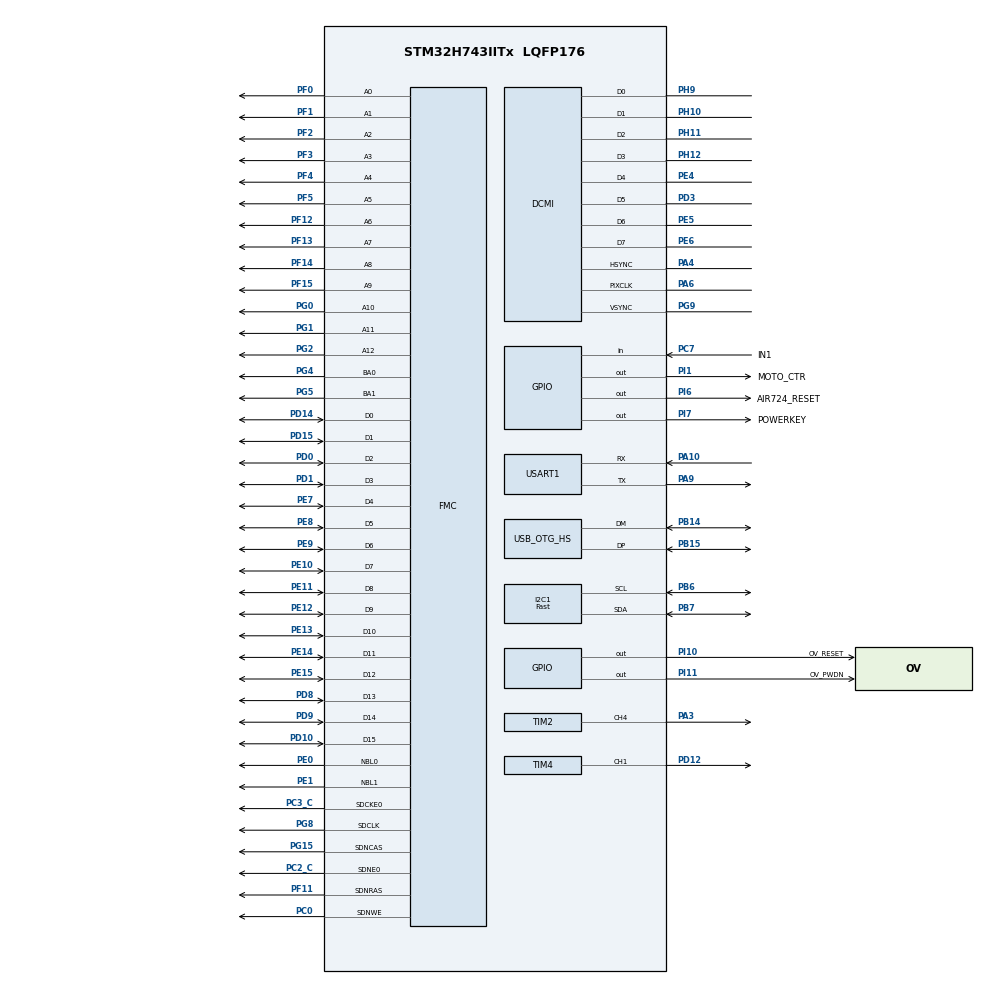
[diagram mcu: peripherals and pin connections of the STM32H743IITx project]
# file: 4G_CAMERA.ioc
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CORTEX_M7.AccessPermission_Spec=MPU_REGION_FULL_ACCESS
CORTEX_M7.BaseAddress_Spec=0x24000000
CORTEX_M7.CPU_DCache=Enabled
CORTEX_M7.CPU_ICache=Enabled
CORTEX_M7.DisableExec_Spec=MPU_INSTRUCTION_ACCESS_ENABLE
CORTEX_M7.Enable_S-Cortex_Memory_Protection_Unit_Region1_Settings_S=__NULL
CORTEX_M7.IsBufferable_Spec=MPU_ACCESS_BUFFERABLE
CORTEX_M7.IsCacheable_Spec=MPU_ACCESS_CACHEABLE
CORTEX_M7.IsShareable_Spec=MPU_ACCESS_NOT_SHAREABLE
CORTEX_M7.MPU_Control=MPU_PRIVILEGED_DEFAULT
CORTEX_M7.Size_Spec=MPU_REGION_SIZE_512KB
CORTEX_M7.SubRegionDisable_Spec=0x0
CORTEX_M7.TypeExtField_Spec=MPU_TEX_LEVEL0
CORTEX_M7.default_mode_Activation=1
DCMI.HSPolarity=DCMI_HSPOLARITY_LOW
DCMI.JPEGMode=DCMI_JPEG_DISABLE
DCMI.PCKPolarity=DCMI_PCKPOLARITY_RISING
DCMI.VSPolarity=DCMI_VSPOLARITY_HIGH
Dma.DCMI.0.Direction=DMA_PERIPH_TO_MEMORY
Dma.DCMI.0.EventEnable=DISABLE
Dma.DCMI.0.FIFOMode=DMA_FIFOMODE_ENABLE
Dma.DCMI.0.FIFOThreshold=DMA_FIFO_THRESHOLD_FULL
Dma.DCMI.0.Instance=DMA1_Stream0
Dma.DCMI.0.MemBurst=DMA_MBURST_SINGLE
Dma.DCMI.0.MemDataAlignment=DMA_MDATAALIGN_WORD
Dma.DCMI.0.MemInc=DMA_MINC_ENABLE
Dma.DCMI.0.Mode=DMA_NORMAL
Dma.DCMI.0.PeriphBurst=DMA_PBURST_SINGLE
Dma.DCMI.0.PeriphDataAlignment=DMA_PDATAALIGN_WORD
Dma.DCMI.0.PeriphInc=DMA_PINC_DISABLE
Dma.DCMI.0.Polarity=HAL_DMAMUX_REQ_GEN_RISING
Dma.DCMI.0.Priority=DMA_PRIORITY_VERY_HIGH
Dma.DCMI.0.RequestNumber=1
Dma.DCMI.0.SignalID=NONE
Dma.DCMI.0.SyncEnable=DISABLE
Dma.DCMI.0.SyncPolarity=HAL_DMAMUX_SYNC_NO_EVENT
Dma.DCMI.0.SyncRequestNumber=1
Dma.DCMI.0.SyncSignalID=NONE
Dma.Request0=DCMI
FMC.CASLatency1=FMC_SDRAM_CAS_LATENCY_3
FMC.ColumnBitsNumber1=FMC_SDRAM_COLUMN_BITS_NUM_9
FMC.ExitSelfRefreshDelay1=8
FMC.LoadToActiveDelay1=2
FMC.RCDDelay1=2
FMC.RPDelay1=2
FMC.ReadBurst1=FMC_SDRAM_RBURST_ENABLE
FMC.ReadPipeDelay1=FMC_SDRAM_RPIPE_DELAY_1
FMC.RowCycleDelay1=6
FMC.SDClockPeriod1=FMC_SDRAM_CLOCK_PERIOD_2
FMC.SelfRefreshTime1=6
FMC.WriteRecoveryTime1=6
FREERTOS.Tasks01=defaultTask,24,128,StartDefaultTask,Default,NULL,Dynamic,NULL,NULL;cmdAnalysis,31,512,StartCmdAnalysis,Default,NULL,Dynamic,NULL,NULL;sendDataTask,30,512,StartSendDataTask,Default,NULL,Dynamic,NULL,NULL;ledTask,23,128,StartLedTask,Default,NULL,Dynamic,NULL,NULL;motoTask,8,128,StartMotoTask,Default,NULL,Dynamic,NULL,NULL
FREERTOS.configENABLE_FPU=1
I2C1.I2C_Speed_Mode=I2C_Fast
I2C1.Timing=0x00B03FDB
IWDG1.Prescaler=IWDG_PRESCALER_32
IWDG1.Reload=2000
JPEG.JPEG_RGB_FORMAT=JPEG_RGB565
JPEG.JPEG_SWAP_RG=0
Mcu.Family=STM32H7
Mcu.Name=STM32H743IITx
Mcu.Package=LQFP176
NVIC.DCMI_IRQn=true\:5\:0\:false\:false\:true\:true\:true\:true\:true
NVIC.DMA1_Stream0_IRQn=true\:5\:0\:false\:false\:true\:true\:false\:true\:true
NVIC.OTG_HS_IRQn=true\:5\:0\:false\:false\:true\:true\:false\:true\:true
NVIC.PriorityGroup=NVIC_PRIORITYGROUP_4
NVIC.RTC_WKUP_IRQn=true\:5\:0\:false\:false\:true\:true\:true\:true\:true
NVIC.TIM17_IRQn=true\:15\:0\:false\:false\:true\:false\:false\:true\:true
NVIC.TimeBase=TIM17_IRQn
NVIC.TimeBaseIP=TIM17
NVIC.USART1_IRQn=true\:5\:0\:false\:false\:true\:true\:true\:true\:true
PA10.Mode=Asynchronous
PA10.Signal=USART1_RX
PA13\ (JTMS/SWDIO).Mode=Serial_Wire
PA13\ (JTMS/SWDIO).Signal=DEBUG_JTMS-SWDIO
PA14\ (JTCK/SWCLK).Mode=Serial_Wire
PA14\ (JTCK/SWCLK).Signal=DEBUG_JTCK-SWCLK
PA3.Signal=S_TIM2_CH4
PA4.Mode=Slave_8_bits_External_Synchro
PA4.Signal=DCMI_HSYNC
PA6.Mode=Slave_8_bits_External_Synchro
PA6.Signal=DCMI_PIXCLK
PA9.Mode=Asynchronous
PA9.Signal=USART1_TX
PB14.Mode=Device_Only_FS
PB14.Signal=USB_OTG_HS_DM
PB15.Mode=Device_Only_FS
PB15.Signal=USB_OTG_HS_DP
PB6.Mode=I2C
PB6.Signal=I2C1_SCL
PB7.Mode=I2C
PB7.Signal=I2C1_SDA
PC0.Signal=FMC_SDNWE
PC14-OSC32_IN\ (OSC32_IN).Mode=LSE-External-Clock-Source
PC14-OSC32_IN\ (OSC32_IN).Signal=RCC_OSC32_IN
PC2_C.Mode=SdramChipSelect1_1
PC2_C.Signal=FMC_SDNE0
PC3_C.Mode=SdramChipSelect1_1
PC3_C.Signal=FMC_SDCKE0
PC7.GPIO_Label=IN1
PC7.Signal=GPIO_Input
PD0.Signal=FMC_D2_DA2
PD1.Signal=FMC_D3_DA3
PD10.Signal=FMC_D15_DA15
PD12.Signal=S_TIM4_CH1
PD14.Signal=FMC_D0_DA0
PD15.Signal=FMC_D1_DA1
PD3.Mode=Slave_8_bits_External_Synchro
PD3.Signal=DCMI_D5
PD8.Signal=FMC_D13_DA13
PD9.Signal=FMC_D14_DA14
PE0.Signal=FMC_NBL0
PE1.Signal=FMC_NBL1
PE10.Signal=FMC_D7_DA7
PE11.Signal=FMC_D8_DA8
PE12.Signal=FMC_D9_DA9
PE13.Signal=FMC_D10_DA10
PE14.Signal=FMC_D11_DA11
PE15.Signal=FMC_D12_DA12
PE4.Mode=Slave_8_bits_External_Synchro
PE4.Signal=DCMI_D4
PE5.Mode=Slave_8_bits_External_Synchro
PE5.Signal=DCMI_D6
PE6.Mode=Slave_8_bits_External_Synchro
PE6.Signal=DCMI_D7
PE7.Signal=FMC_D4_DA4
PE8.Signal=FMC_D5_DA5
PE9.Signal=FMC_D6_DA6
PF0.Signal=FMC_A0
PF1.Signal=FMC_A1
PF11.Signal=FMC_SDNRAS
PF12.Signal=FMC_A6
PF13.Signal=FMC_A7
PF14.Signal=FMC_A8
PF15.Signal=FMC_A9
PF2.Signal=FMC_A2
PF3.Signal=FMC_A3
PF4.Signal=FMC_A4
PF5.Signal=FMC_A5
PG0.Signal=FMC_A10
PG1.Signal=FMC_A11
PG15.Signal=FMC_SDNCAS
PG2.Signal=FMC_A12
PG4.Signal=FMC_A14_BA0
PG5.Signal=FMC_A15_BA1
PG8.Signal=FMC_SDCLK
PG9.Mode=Slave_8_bits_External_Synchro
PG9.Signal=DCMI_VSYNC
PH0-OSC_IN\ (PH0).Mode=HSE-External-Clock-Source
PH0-OSC_IN\ (PH0).Signal=RCC_OSC_IN
PH10.Mode=Slave_8_bits_External_Synchro
PH10.Signal=DCMI_D1
PH11.Mode=Slave_8_bits_External_Synchro
PH11.Signal=DCMI_D2
PH12.Mode=Slave_8_bits_External_Synchro
PH12.Signal=DCMI_D3
PH9.Mode=Slave_8_bits_External_Synchro
PH9.Signal=DCMI_D0
PI1.GPIO_Label=MOTO_CTR
PI1.GPIO_PuPd=GPIO_PULLUP
PI1.GPIO_Speed=GPIO_SPEED_FREQ_VERY_HIGH
PI1.Signal=GPIO_Output
PI10.GPIO_Label=OV_RESET
PI10.GPIO_PuPd=GPIO_PULLUP
PI10.GPIO_Speed=GPIO_SPEED_FREQ_VERY_HIGH
PI10.Signal=GPIO_Output
PI11.GPIO_Label=OV_PWDN
PI11.GPIO_ModeDefaultOutputPP=GPIO_MODE_OUTPUT_PP
PI11.GPIO_PuPd=GPIO_PULLUP
PI11.GPIO_Speed=GPIO_SPEED_FREQ_VERY_HIGH
PI11.Signal=GPIO_Output
PI6.GPIO_Label=AIR724_RESET
PI6.GPIO_PuPd=GPIO_PULLUP
PI6.GPIO_Speed=GPIO_SPEED_FREQ_VERY_HIGH
PI6.Signal=GPIO_Output
PI7.GPIO_Label=POWERKEY
PI7.GPIO_PuPd=GPIO_PULLUP
PI7.GPIO_Speed=GPIO_SPEED_FREQ_VERY_HIGH
PI7.Signal=GPIO_Output
ProjectManager.HeapSize=0x200
ProjectManager.StackSize=0x400
ProjectManager.TargetToolchain=MDK-ARM V5.32
RCC.ADCFreq_Value=75000000
RCC.APB1Freq_Value=120000000
RCC.APB2Freq_Value=120000000
RCC.APB3Freq_Value=120000000
RCC.APB4Freq_Value=120000000
RCC.CortexFreq_Value=480000000
RCC.D1PPRE=RCC_APB3_DIV2
RCC.D2PPRE1=RCC_APB1_DIV2
RCC.D2PPRE2=RCC_APB2_DIV2
RCC.D3PPRE=RCC_APB4_DIV2
RCC.DIVM1=1
RCC.DIVM2=1
RCC.DIVN1=80
RCC.DIVN2=12
RCC.DIVQ1=4
RCC.DIVR2=1
RCC.FMCCLockSelection=RCC_FMCCLKSOURCE_PLL2
RCC.HCLKFreq_Value=240000000
RCC.HPRE=RCC_HCLK_DIV2
RCC.HSE_VALUE=12000000
RCC.PLL2FRACN=4096
RCC.PLL3FRACN=0
RCC.PLLFRACN=0
RCC.PLLSourceVirtual=RCC_PLLSOURCE_HSE
RCC.ProductRev=revV
RCC.RCC_MCO1Source=RCC_MCO1SOURCE_HSE
RCC.RCC_MCO2Source=RCC_MCO2SOURCE_PLL2PCLK
RCC.RCC_TIM_PRescaler_Selection=RCC_TIMPRES_DESACTIVATED
RCC.RTCClockSelection=RCC_RTCCLKSOURCE_LSE
RCC.SYSCLKFreq_VALUE=480000000
RCC.SYSCLKSource=RCC_SYSCLKSOURCE_PLLCLK
RCC.SupplySource=PWR_LDO_SUPPLY
RCC.USBCLockSelection=RCC_USBCLKSOURCE_HSI48
RCC.USBFreq_Value=48000000
RTC.WakeUpClock-WakeUp=RTC_WAKEUPCLOCK_CK_SPRE_16BITS
RTC.WakeUpCounter-WakeUp=0
SH.FMC_A0.0=FMC_A0,13b-sda1
SH.FMC_A1.0=FMC_A1,13b-sda1
SH.FMC_A10.0=FMC_A10,13b-sda1
SH.FMC_A11.0=FMC_A11,13b-sda1
SH.FMC_A12.0=FMC_A12,13b-sda1
SH.FMC_A14_BA0.0=FMC_BA0,FourSdramBanks1
SH.FMC_A15_BA1.0=FMC_BA1,FourSdramBanks1
SH.FMC_A2.0=FMC_A2,13b-sda1
SH.FMC_A3.0=FMC_A3,13b-sda1
SH.FMC_A4.0=FMC_A4,13b-sda1
SH.FMC_A5.0=FMC_A5,13b-sda1
SH.FMC_A6.0=FMC_A6,13b-sda1
SH.FMC_A7.0=FMC_A7,13b-sda1
SH.FMC_A8.0=FMC_A8,13b-sda1
SH.FMC_A9.0=FMC_A9,13b-sda1
SH.FMC_D0_DA0.0=FMC_D0,sd-16b-d1
SH.FMC_D10_DA10.0=FMC_D10,sd-16b-d1
SH.FMC_D11_DA11.0=FMC_D11,sd-16b-d1
SH.FMC_D12_DA12.0=FMC_D12,sd-16b-d1
SH.FMC_D13_DA13.0=FMC_D13,sd-16b-d1
SH.FMC_D14_DA14.0=FMC_D14,sd-16b-d1
SH.FMC_D15_DA15.0=FMC_D15,sd-16b-d1
SH.FMC_D1_DA1.0=FMC_D1,sd-16b-d1
SH.FMC_D2_DA2.0=FMC_D2,sd-16b-d1
SH.FMC_D3_DA3.0=FMC_D3,sd-16b-d1
SH.FMC_D4_DA4.0=FMC_D4,sd-16b-d1
SH.FMC_D5_DA5.0=FMC_D5,sd-16b-d1
SH.FMC_D6_DA6.0=FMC_D6,sd-16b-d1
SH.FMC_D7_DA7.0=FMC_D7,sd-16b-d1
SH.FMC_D8_DA8.0=FMC_D8,sd-16b-d1
SH.FMC_D9_DA9.0=FMC_D9,sd-16b-d1
SH.FMC_NBL0.0=FMC_NBL0,Sd2ByteEnable1
SH.FMC_NBL1.0=FMC_NBL1,Sd2ByteEnable1
SH.FMC_SDCLK.0=FMC_SDCLK,13b-sda1
SH.FMC_SDNCAS.0=FMC_SDNCAS,13b-sda1
SH.FMC_SDNRAS.0=FMC_SDNRAS,13b-sda1
SH.FMC_SDNWE.0=FMC_SDNWE,13b-sda1
SH.S_TIM2_CH4.0=TIM2_CH4,PWM Generation4 CH4
SH.S_TIM4_CH1.0=TIM4_CH1,PWM Generation1 CH1
TIM2.Channel-PWM\ Generation4\ CH4=TIM_CHANNEL_4
TIM2.Period=100
TIM2.Prescaler=199
TIM4.Channel-PWM\ Generation1\ CH1=TIM_CHANNEL_1
TIM4.Period=100
TIM4.Prescaler=199
USART1.VirtualMode-Asynchronous=VM_ASYNC
USB_DEVICE.CLASS_NAME_HS=CDC
USB_DEVICE.VirtualMode-CDC_HS=Cdc
USB_DEVICE.VirtualModeHS=Cdc_HS
USB_OTG_HS.VirtualMode-Device_Only_FS=Device_Only_FS
VP_FREERTOS_VS_CMSIS_V2.Mode=CMSIS_V2
VP_IWDG1_VS_IWDG.Mode=IWDG_Activate
VP_JPEG_VS_JPEG.Mode=JPEG_Activate
VP_RTC_VS_RTC_Activate.Mode=RTC_Enabled
VP_RTC_VS_RTC_WakeUp_intern.Mode=WakeUp
VP_SYS_VS_tim17.Mode=TIM17
VP_TIM2_VS_ClockSourceINT.Mode=Internal
VP_TIM4_VS_ClockSourceINT.Mode=Internal
VP_USB_DEVICE_VS_USB_DEVICE_CDC_HS.Mode=CDC_HS
board=custom

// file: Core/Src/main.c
/* USER CODE BEGIN Header */
/**
  ******************************************************************************
  * @file           : main.c
  * @brief          : Main program body
  ******************************************************************************
  * @attention
  *
  * Copyright (c) 2024 STMicroelectronics.
  * All rights reserved.
  *
  * This software is licensed under terms that can be found in the LICENSE file
  * in the root directory of this software component.
  * If no LICENSE file comes with this software, it is provided AS-IS.
  *
  ******************************************************************************
  */
/* USER CODE END Header */
#include "main.h"
#include "cmsis_os.h"
#include "dcmi.h"
#include "dma.h"
#include "i2c.h"
#include "iwdg.h"
#include "jpeg.h"
#include "rtc.h"
#include "tim.h"
#include "usart.h"
#include "usb_device.h"
#include "gpio.h"
#include "fmc.h"

/* USER CODE BEGIN Includes */
#include "sdram.h"
#include "ov5640.h"
#include "flash.h"
#include "stm32h7xx_it.h"
/* USER CODE END Includes */

/* USER CODE BEGIN PV */
uint32_t dcmi_data_buff[RGB_DATA_BUFFER_SIZE/4];//JPEG数据缓存buf
uint32_t jpgDataBuffer[JPG_DATA_BUFFER_SIZE/4];

MY_TIM time;

uint32_t sysclock = 0;

_deviceInfo deviceAttributeInfo;
/* USER CODE END PV */

void SystemClock_Config(void);
static void MPU_Initialize(void);
static void MPU_Config(void);
void MX_FREERTOS_Init(void);
/* USER CODE BEGIN PFP */
uint32_t bsp_TestExtSDRAM(void);
/* USER CODE END PFP */

int main(void)
{
  /* USER CODE BEGIN 1 */
	SCB->VTOR = 0x08020000;   //APP下载的地址
  /* USER CODE END 1 */

  /* Enable I-Cache---------------------------------------------------------*/
  SCB_EnableICache();

  /* Enable D-Cache---------------------------------------------------------*/
  SCB_EnableDCache();

  /* MCU Configuration--------------------------------------------------------*/

  /* Reset of all peripherals, Initializes the Flash interface and the Systick. */
  HAL_Init();

  /* MPU Configuration--------------------------------------------------------*/
  MPU_Config();

  /* Configure the system clock */
  SystemClock_Config();

  /* Initialize all configured peripherals */
  MX_GPIO_Init();
  MX_DMA_Init();
  MX_DCMI_Init();
  MX_USART1_UART_Init();
  MX_TIM2_Init();
  MX_I2C1_Init();
  MX_FMC_Init();
  MX_JPEG_Init();
  MX_RTC_Init();
  MX_TIM4_Init();
  MX_IWDG1_Init();
  /* USER CODE BEGIN 2 */
	//这里必须选清除wakeup中断标志位，否则可能触发不了中断
	__HAL_RTC_WAKEUPTIMER_CLEAR_FLAG(&hrtc, RTC_FLAG_WUTF);
	sysclock = HAL_RCC_GetSysClockFreq();

	bsp_ReadCpuFlash(ADDR_FLASH_SECTOR_7_BANK2,(uint8_t *)&deviceAttributeInfo.wifiName[0],sizeof(deviceAttributeInfo));
	deviceAttributeInfo.sysState = SYS_OK_STATE;
	HAL_UART_Receive_IT(&huart1,&uartTempData,1); //使能串口1的接收中断

  if(OV5640_INIT_OK != OV5640_Init())
	{
		deviceAttributeInfo.sysState = CAMERA_ERROR_STATE;
	}

	if(1 == deviceAttributeInfo.automaticFocus)
	{
		OV5640_Focus_Constant();
		OV5640_Focus_Init();
	}
	bsp_TestExtSDRAM();

	HAL_TIM_PWM_Start(&htim2,TIM_CHANNEL_4);			//使能TIM2 CH4 PWM输出
	HAL_TIM_PWM_Start(&htim4,TIM_CHANNEL_1);			//使能TIM4 CH1 PWM输出

  /* USER CODE END 2 */

  /* Init scheduler */
  osKernelInitialize();  /* Call init function for freertos objects (in freertos.c) */
  MX_FREERTOS_Init();

  /* Start scheduler */
  osKernelStart();

  /* We should never get here as control is now taken by the scheduler */
  /* Infinite loop */
  while (1)
  {

  }
}

void SystemClock_Config(void)
{
  RCC_OscInitTypeDef RCC_OscInitStruct = {0};
  RCC_ClkInitTypeDef RCC_ClkInitStruct = {0};

  /** Supply configuration update enable
  */
  HAL_PWREx_ConfigSupply(PWR_LDO_SUPPLY);

  /** Configure the main internal regulator output voltage
  */
  __HAL_PWR_VOLTAGESCALING_CONFIG(PWR_REGULATOR_VOLTAGE_SCALE1);

  while(!__HAL_PWR_GET_FLAG(PWR_FLAG_VOSRDY)) {}

  __HAL_RCC_SYSCFG_CLK_ENABLE();
  __HAL_PWR_VOLTAGESCALING_CONFIG(PWR_REGULATOR_VOLTAGE_SCALE0);

  while(!__HAL_PWR_GET_FLAG(PWR_FLAG_VOSRDY)) {}

  /** Initializes the RCC Oscillators according to the specified parameters
  * in the RCC_OscInitTypeDef structure.
  */
  RCC_OscInitStruct.OscillatorType = RCC_OSCILLATORTYPE_HSI48|RCC_OSCILLATORTYPE_LSI
                              |RCC_OSCILLATORTYPE_HSE|RCC_OSCILLATORTYPE_LSE;
  RCC_OscInitStruct.HSEState = RCC_HSE_BYPASS;
  RCC_OscInitStruct.LSEState = RCC_LSE_BYPASS;
  RCC_OscInitStruct.LSIState = RCC_LSI_ON;
  RCC_OscInitStruct.HSI48State = RCC_HSI48_ON;
  RCC_OscInitStruct.PLL.PLLState = RCC_PLL_ON;
  RCC_OscInitStruct.PLL.PLLSource = RCC_PLLSOURCE_HSE;
  RCC_OscInitStruct.PLL.PLLM = 1;
  RCC_OscInitStruct.PLL.PLLN = 80;
  RCC_OscInitStruct.PLL.PLLP = 2;
  RCC_OscInitStruct.PLL.PLLQ = 4;
  RCC_OscInitStruct.PLL.PLLR = 2;
  RCC_OscInitStruct.PLL.PLLRGE = RCC_PLL1VCIRANGE_3;
  RCC_OscInitStruct.PLL.PLLVCOSEL = RCC_PLL1VCOWIDE;
  RCC_OscInitStruct.PLL.PLLFRACN = 0;
  if (HAL_RCC_OscConfig(&RCC_OscInitStruct) != HAL_OK)
  {
    Error_Handler();
  }

  /** Initializes the CPU, AHB and APB buses clocks
  */
  RCC_ClkInitStruct.ClockType = RCC_CLOCKTYPE_HCLK|RCC_CLOCKTYPE_SYSCLK
                              |RCC_CLOCKTYPE_PCLK1|RCC_CLOCKTYPE_PCLK2
                              |RCC_CLOCKTYPE_D3PCLK1|RCC_CLOCKTYPE_D1PCLK1;
  RCC_ClkInitStruct.SYSCLKSource = RCC_SYSCLKSOURCE_PLLCLK;
  RCC_ClkInitStruct.SYSCLKDivider = RCC_SYSCLK_DIV1;
  RCC_ClkInitStruct.AHBCLKDivider = RCC_HCLK_DIV2;
  RCC_ClkInitStruct.APB3CLKDivider = RCC_APB3_DIV2;
  RCC_ClkInitStruct.APB1CLKDivider = RCC_APB1_DIV2;
  RCC_ClkInitStruct.APB2CLKDivider = RCC_APB2_DIV2;
  RCC_ClkInitStruct.APB4CLKDivider = RCC_APB4_DIV2;

  if (HAL_RCC_ClockConfig(&RCC_ClkInitStruct, FLASH_LATENCY_4) != HAL_OK)
  {
    Error_Handler();
  }
}

/* USER CODE BEGIN 4 */

uint32_t bsp_TestExtSDRAM(void)
{
	uint32_t i;
	uint32_t *pSRAM;
	uint8_t *pBytes;
	uint32_t err;
	const uint8_t ByteBuf[4] = {0x55, 0xA5, 0x5A, 0xAA};

	/* 写SDRAM */
	pSRAM = (uint32_t *)EXT_SDRAM_ADDR;
	for (i = 0; i < EXT_SDRAM_SIZE / 4; i++)
	{
		*pSRAM++ = i;
	}

	/* 读SDRAM */
	err = 0;
	pSRAM = (uint32_t *)EXT_SDRAM_ADDR;
	for (i = 0; i < EXT_SDRAM_SIZE / 4; i++)
	{
		if (*pSRAM++ != i)
		{
			err++;
		}
	}

	if (err >  0)
	{
		return  (4 * err);
	}

	/* 对SDRAM 的数据求反并写入 */
	pSRAM = (uint32_t *)EXT_SDRAM_ADDR;
	for (i = 0; i < EXT_SDRAM_SIZE / 4; i++)
	{
		*pSRAM = ~*pSRAM;
		pSRAM++;
	}

	/* 再次比较SDRAM的数据 */
	err = 0;
	pSRAM = (uint32_t *)EXT_SDRAM_ADDR;
	for (i = 0; i < EXT_SDRAM_SIZE / 4; i++)
	{
		if (*pSRAM++ != (~i))
		{
			err++;
		}
	}

	if (err >  0)
	{
		return (4 * err);
	}

	/* 测试按字节方式访问, 目的是验证 FSMC_NBL0 、 FSMC_NBL1 口线 */
	pBytes = (uint8_t *)EXT_SDRAM_ADDR;
	for (i = 0; i < sizeof(ByteBuf); i++)
	{
		*pBytes++ = ByteBuf[i];
	}

	/* 比较SDRAM的数据 */
	err = 0;
	pBytes = (uint8_t *)EXT_SDRAM_ADDR;
	for (i = 0; i < sizeof(ByteBuf); i++)
	{
		if (*pBytes++ != ByteBuf[i])
		{
			err++;
		}
	}
	if (err >  0)
	{
		return err;
	}
	return 0;
}
/* USER CODE END 4 */

/* MPU Configuration */

void MPU_Config(void)
{
  MPU_Region_InitTypeDef MPU_InitStruct = {0};

  /* Disables the MPU */
  HAL_MPU_Disable();

  /** Initializes and configures the Region and the memory to be protected
  */
  MPU_InitStruct.Enable = MPU_REGION_ENABLE;
  MPU_InitStruct.Number = MPU_REGION_NUMBER0;
  MPU_InitStruct.BaseAddress = 0x24000000;
  MPU_InitStruct.Size = MPU_REGION_SIZE_512KB;
  MPU_InitStruct.SubRegionDisable = 0x0;
  MPU_InitStruct.TypeExtField = MPU_TEX_LEVEL0;
  MPU_InitStruct.AccessPermission = MPU_REGION_FULL_ACCESS;
  MPU_InitStruct.DisableExec = MPU_INSTRUCTION_ACCESS_ENABLE;
  MPU_InitStruct.IsShareable = MPU_ACCESS_NOT_SHAREABLE;
  MPU_InitStruct.IsCacheable = MPU_ACCESS_CACHEABLE;
  MPU_InitStruct.IsBufferable = MPU_ACCESS_BUFFERABLE;

  HAL_MPU_ConfigRegion(&MPU_InitStruct);
  /* Enables the MPU */
  HAL_MPU_Enable(MPU_PRIVILEGED_DEFAULT);

}

void HAL_TIM_PeriodElapsedCallback(TIM_HandleTypeDef *htim)
{
  if (htim->Instance == TIM17) {
    HAL_IncTick();
  }
}

void Error_Handler(void)
{
  __disable_irq();
  while (1)
  {
  }
}

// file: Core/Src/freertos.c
/* USER CODE BEGIN Header */
/**
  ******************************************************************************
  * File Name          : freertos.c
  * Description        : Code for freertos applications
  ******************************************************************************
  * @attention
  *
  * Copyright (c) 2024 STMicroelectronics.
  * All rights reserved.
  *
  * This software is licensed under terms that can be found in the LICENSE file
  * in the root directory of this software component.
  * If no LICENSE file comes with this software, it is provided AS-IS.
  *
  ******************************************************************************
  */
/* USER CODE END Header */

#include "FreeRTOS.h"
#include "task.h"
#include "main.h"
#include "cmsis_os.h"

/* USER CODE BEGIN Includes */
#include "dcmi.h"
#include "jpeg.h"
#include "jpeg_utils.h"
#include "usbd_cdc_if.h"
#include "main.h"
#include "usart.h"
#include "ringBuffer.h"
#include "usbd_cdc_if.h"
#include "flash.h"
#include "tim.h"
#include "air724.h"
#include "ov5640.h"
/* USER CODE END Includes */

/* USER CODE BEGIN Variables */
char air724InitOk = 1;
char getTackPictureFlag = 0;
char takePictureFlag = 0;
char openMotoFlag = 0;
uint32_t lastSec = 0;
char anlysis = 0;

uint8_t takePictureTestModeFlag = 0;

uint8_t serverIsOk = 0;
/* USER CODE END Variables */
/* Definitions for defaultTask */
osThreadId_t defaultTaskHandle;
const osThreadAttr_t defaultTask_attributes = {
  .name = "defaultTask",
  .stack_size = 128 * 4,
  .priority = (osPriority_t) osPriorityNormal,
};
/* Definitions for cmdAnalysis */
osThreadId_t cmdAnalysisHandle;
const osThreadAttr_t cmdAnalysis_attributes = {
  .name = "cmdAnalysis",
  .stack_size = 512 * 4,
  .priority = (osPriority_t) osPriorityNormal7,
};
/* Definitions for sendDataTask */
osThreadId_t sendDataTaskHandle;
const osThreadAttr_t sendDataTask_attributes = {
  .name = "sendDataTask",
  .stack_size = 512 * 4,
  .priority = (osPriority_t) osPriorityNormal6,
};
/* Definitions for ledTask */
osThreadId_t ledTaskHandle;
const osThreadAttr_t ledTask_attributes = {
  .name = "ledTask",
  .stack_size = 128 * 4,
  .priority = (osPriority_t) osPriorityBelowNormal7,
};
/* Definitions for motoTask */
osThreadId_t motoTaskHandle;
const osThreadAttr_t motoTask_attributes = {
  .name = "motoTask",
  .stack_size = 128 * 4,
  .priority = (osPriority_t) osPriorityLow,
};

/* USER CODE BEGIN FunctionPrototypes */
static uint8_t vcpSendData(uint8_t frameHead, uint8_t frameAddress, uint8_t frameID, uint8_t* data,uint8_t dataLen);
static uint8_t sendLogMessage(unsigned char frameHead, unsigned char frameAddress, unsigned char frameID, char* data);
static void showDeviceInfo(void);
static void vcpDataAnalysis(_RingBuffer *ringbuffer);
static void usart1DataAnalysis(_RingBuffer *ringbuffer);

static void frameDataAnalysis(uint8_t *data,uint32_t dataLen);
static void serverToClient(uint8_t *data);
static void pcToCameraDeal(uint8_t *data);
static void packTcpDataFrameAndSend(uint8_t charactar,uint8_t target, uint8_t cmd, uint32_t dataLen, uint8_t *data);

static void takePictureOnTestMode(void);
static void takePictureCameraToPc(void);
static void takePictureCameraToServer(void);
static void skipFrame(void);
/* USER CODE END FunctionPrototypes */

void StartDefaultTask(void *argument);
void StartCmdAnalysis(void *argument);
void StartSendDataTask(void *argument);
void StartLedTask(void *argument);
void StartMotoTask(void *argument);

extern void MX_USB_DEVICE_Init(void);
void MX_FREERTOS_Init(void); /* (MISRA C 2004 rule 8.1) */

void MX_FREERTOS_Init(void) {

  /* Create the thread(s) */
  /* creation of defaultTask */
  defaultTaskHandle = osThreadNew(StartDefaultTask, NULL, &defaultTask_attributes);

  /* creation of cmdAnalysis */
  cmdAnalysisHandle = osThreadNew(StartCmdAnalysis, NULL, &cmdAnalysis_attributes);

  /* creation of sendDataTask */
  sendDataTaskHandle = osThreadNew(StartSendDataTask, NULL, &sendDataTask_attributes);

  /* creation of ledTask */
  ledTaskHandle = osThreadNew(StartLedTask, NULL, &ledTask_attributes);

  /* creation of motoTask */
  motoTaskHandle = osThreadNew(StartMotoTask, NULL, &motoTask_attributes);

}

void StartDefaultTask(void *argument)
{
  /* init code for USB_DEVICE */
  MX_USB_DEVICE_Init();
  /* USER CODE BEGIN StartDefaultTask */
	uint16_t reTryCnt = 0;
	while(AIR724_INIT_OK != air724Init() && reTryCnt<10)
	{
		deviceAttributeInfo.sysState = AIR724_ERROR_STATE;
		reTryCnt++;
		HAL_Delay(5000);
	}
	if(10 == reTryCnt)
	{
		deviceAttributeInfo.sysState = AIR724_ERROR_STATE;
		air724InitOk = 1;
	}
	else
	{
		deviceAttributeInfo.sysState = SYS_OK_STATE;
		air724InitOk = AIR724_INIT_OK;
	}
  /* Infinite loop */
  for(;;)
  {
    osDelay(1);
  }
  /* USER CODE END StartDefaultTask */
}

void StartCmdAnalysis(void *argument)
{
  /* USER CODE BEGIN StartCmdAnalysis */
  /* Infinite loop */
  for(;;)
  {
		vcpDataAnalysis(&VCP_RxRingBuffer);
		if(anlysis == 1)
			usart1DataAnalysis(&UART_RxRingBuffer);
    osDelay(100);
  }
  /* USER CODE END StartCmdAnalysis */
}

void StartSendDataTask(void *argument)
{
  /* USER CODE BEGIN StartSendDataTask */
	skipFrame();	/* 跳过最开始的几帧图像 */
  while(1 == air724InitOk)
	{
		osDelay(1000);
	}
  /* Infinite loop */
	/* 固定定时时间判断 */
	static unsigned char timeArrive = 0;
	char timeCmp[6];
	char logBuffer[100];
	lastSec = time.hour * 60 + time.minute;
	takePictureFlag = 0;

//	uint8_t takePictureOverTime = 0;

	JPEG_InitColorTables();

  for(;;)
  {
    /*************************************************************************发送TCP心跳包**********************************************************************************************/
		static uint8_t heartBeatTimeCnt = 0;		/* 不执行耗时的操作时，是10ms循环一次 */
		if(heartBeatTimeCnt == 200)
		{
				packTcpDataFrameAndSend(DEVICE_LABEL_CAMERA,CAMER_TO_SERVER,HERAT_BEAT_PACK,0,0);
				heartBeatTimeCnt = 0;
		}
		heartBeatTimeCnt++;
		/*************************************************************************服务器检测**********************************************************************************************/
		static uint16_t serverTryCheckTimeCnt = 0;		/* 不执行耗时的操作时，是10ms循环一次 */
		uint8_t tryCnt = 0;
		if(serverTryCheckTimeCnt == 1000)
		{
				serverIsOk = 1;
				while(serverIsOk)
				{
					packTcpDataFrameAndSend(DEVICE_LABEL_CAMERA,CAMER_TO_SERVER,CAMERA_TRY_SERVER_CHECK,0,0);
					if(tryCnt == 100)/* 2s内没有响应 */
					{
						NVIC_SystemReset();
					}
					tryCnt++;
					vTaskDelay(pdMS_TO_TICKS(20));
				}
				serverTryCheckTimeCnt = 0;
		}
		serverTryCheckTimeCnt++;
		/*************************************************************************测试模式**********************************************************************************************/
		if(SYS_TEST_MODE_SATE == deviceAttributeInfo.sysState)
		{
			sprintf(timeCmp,"%02d:%02d",time.hour,time.minute);
			for(int i=0;i<50;i++)
			{
					if(strcmp(timeCmp,deviceAttributeInfo.recordTime[i]) == 0 && timeArrive != i)
					{
							takePictureTestModeFlag = 1;
							timeArrive = i;
							sendLogMessage(0xAA,MCU,CMD_LOG_MESSAGE,"\xe5\x9b\xba\xe5\xae\x9a\xe5\xae\x9a\xe6\x97\xb6\xe9\x97\xb4\xe5\x88\xb0");/* 固定定时时间到 */
					}
			}
			/*******************************************************************************间隔定时判断**********************************************************************************************/
			if(deviceAttributeInfo.scheduledDeletion != 0)/* 定时有效,单位分钟 */
			{
					uint32_t nowSec = time.hour * 60 + time.minute;
					if(nowSec < lastSec)	nowSec+=	24*60;
					if(nowSec - lastSec >= deviceAttributeInfo.scheduledDeletion)
					{
							lastSec = nowSec;
							takePictureFlag = 1;
							takePictureTestModeFlag = 1;
							sendLogMessage(0xAA,MCU,CMD_LOG_MESSAGE,"\xe9\x97\xb4\xe9\x9a\x94\xe5\xae\x9a\xe6\x97\xb6\xe9\x97\xb4\xe5\x88\xb0");/* 间隔定时时间到 */
					}
			}
			if(1 == takePictureTestModeFlag)
			{
				takePictureOnTestMode();
				takePictureTestModeFlag = 0;
			}
		}
		/*************************************************************************正常工作模式**********************************************************************************************/
		else
		{
			/*******************************************************************************固定定时判断**********************************************************************************************/

			sprintf(timeCmp,"%02d:%02d",time.hour,time.minute);
			for(int i=0;i<50;i++)
			{
					if(strcmp(timeCmp,deviceAttributeInfo.recordTime[i]) == 0 && timeArrive != i)
					{
							openMotoFlag = 1;
							takePictureFlag = 1;
							timeArrive = i;
					}
			}
			/*******************************************************************************间隔定时判断**********************************************************************************************/
			if(deviceAttributeInfo.scheduledDeletion != 0)/* 定时有效,单位分钟 */
			{
					uint32_t nowSec = time.hour * 60 + time.minute;
					if(nowSec < lastSec)	nowSec+=	24*60;
					if(nowSec - lastSec >= deviceAttributeInfo.scheduledDeletion)
					{
							lastSec = nowSec;
							openMotoFlag = 1;
							takePictureFlag = 1;
					}
			}
			/*******************************************************************************拍照**********************************************************************************************/
			if(1 == getTackPictureFlag)
			{
				takePictureCameraToPc();
				getTackPictureFlag = 0;
			}
			if(takePictureFlag == 1)
			{
				takePictureCameraToServer();
				takePictureFlag = 0;
			}
			/*******************************************************************************外部电平检测**********************************************************************************************/
			static char keyFlag = 0;
			if(HAL_GPIO_ReadPin(IN1_GPIO_Port,IN1_Pin) == 0 && keyFlag == 0)/* 吸合检测到低电平，水位到达水位线 */
			{
					HAL_GPIO_WritePin(MOTO_CTR_GPIO_Port, MOTO_CTR_Pin, GPIO_PIN_RESET);				//检测到水位到达，立马关闭水泵
					vTaskDelay(pdMS_TO_TICKS(deviceAttributeInfo.takePictureDelayTime*1000));		/* 延时等水箱水位静止 */
					takePictureFlag = 1;
					keyFlag = 1;
			}
			else if(HAL_GPIO_ReadPin(IN1_GPIO_Port,IN1_Pin) == 1 && keyFlag == 1)/* 断开检测到高电平 */
			{
					keyFlag = 0;
			}
			/*********************************************************************************继电器控制****************************************************************************************************/
			if(openMotoFlag == 1 && HAL_GPIO_ReadPin(IN1_GPIO_Port,IN1_Pin) == 1) /* 水位检测开关没有到达水位线，可以打开水泵 */
			{
					HAL_GPIO_WritePin(MOTO_CTR_GPIO_Port, MOTO_CTR_Pin, GPIO_PIN_SET);//打开水泵命令，打开水泵
					openMotoFlag = 0;
			}
		}
		osDelay(10);
  }
  /* USER CODE END StartSendDataTask */
}

void StartLedTask(void *argument)
{
  /* USER CODE BEGIN StartLedTask */
  /* Infinite loop */
  for(;;)
  {

    osDelay(10);
  }
  /* USER CODE END StartLedTask */
}

void StartMotoTask(void *argument)
{
  /* USER CODE BEGIN StartMotoTask */
  /* Infinite loop */
  for(;;)
  {
		/*******************************************************************************外部电平检测**********************************************************************************************/
		static char keyFlag = 0;
		if(HAL_GPIO_ReadPin(IN1_GPIO_Port,IN1_Pin) == 0 && keyFlag == 0)/* 吸合检测到低电平，水位到达水位线 */
		{
				takePictureFlag = 1;
				keyFlag = 1;
				HAL_GPIO_WritePin(MOTO_CTR_GPIO_Port, MOTO_CTR_Pin, GPIO_PIN_RESET);//检测到水位到达，立马关闭水泵
		}
		else if(HAL_GPIO_ReadPin(IN1_GPIO_Port,IN1_Pin) == 1 && keyFlag == 1)/* 断开检测到高电平 */
		{
				keyFlag = 0;
		}
/*********************************************************************************继电器控制****************************************************************************************************/
		if(openMotoFlag == 1 && HAL_GPIO_ReadPin(IN1_GPIO_Port,IN1_Pin) == 1) /* 水位检测开关没有到达水位线，可以打开水泵 */
		{
				HAL_GPIO_WritePin(MOTO_CTR_GPIO_Port, MOTO_CTR_Pin, GPIO_PIN_SET);//打开水泵命令，打开水泵
				openMotoFlag = 0;
		}
		else if(openMotoFlag == 1 && HAL_GPIO_ReadPin(IN1_GPIO_Port,IN1_Pin) == 0)
		{
				//此时就只执行拍照
				takePictureFlag = 1;
				openMotoFlag = 0;
		}
    osDelay(10);
  }
  /* USER CODE END StartMotoTask */
}

/* USER CODE BEGIN Application */
/*
	vcpDataAnalysis(_RingBuffer *ringbuffer)
	功能:解析USB虚拟串口接收的数据
*/
static void vcpDataAnalysis(_RingBuffer *ringbuffer)
{
	char logBuffer[100];
	unsigned char *RxFrameData;/*存储解析帧的空间*/
	unsigned short FrameDataLen = ringbuffer->Lenght;
	if(xPortGetFreeHeapSize() >= FrameDataLen)
	{
		RxFrameData = (unsigned char *)pvPortMalloc(FrameDataLen);	/*为读取缓冲区中的所有数据申请内存*/
		if(ReadBytes(ringbuffer,RxFrameData,FrameDataLen) == 1)		/*读取缓冲区中的所有数据*/
		{
			/*读取到缓冲区的数据*/
			for(int i=0;i<FrameDataLen;i++)	/*遍历*/
			{
				if(RxFrameData[i] == 0xAA)			/*找帧头*/
				{
					if(FrameDataLen - i <= 3)		/*帧头后面无数据长度*/
					{
						WriteBytes(ringbuffer,&RxFrameData[i],FrameDataLen - i);/*未处理的数据写回缓冲区*/
						vPortFree(RxFrameData);  //释放内存
						return ;/*返回空数据*/
					}

					unsigned short FrameLen = RxFrameData[i+3];			/*得到帧数据内容长度*/

					if((FrameDataLen - i) >= (4 + FrameLen + 2))	/*剩余数据是否还有一帧的长度*/
					{
						if(FrameDataCheck( &RxFrameData[i] ) == 1)		/*校验帧数据*/
						{
							unsigned short OneFrameDataLen = 4 + FrameLen + 2;			/*返回帧总长*/
							if(RxFrameData[i+1] == PC)														/*是上位机发送的数据*/
							{
								switch (RxFrameData[i+2])
								{
										case CDM_WIFI_NAME:
										{
												memset(deviceAttributeInfo.wifiName,0,sizeof(deviceAttributeInfo.wifiName));
												memcpy((char *)deviceAttributeInfo.wifiName, &RxFrameData[i+4],FrameLen);
												break;
										}
										case CMD_WIFI_PASSWORD:
										{
												memset(deviceAttributeInfo.wifiPssword,0,sizeof(deviceAttributeInfo.wifiPssword));
												memcpy((char *)deviceAttributeInfo.wifiPssword, &RxFrameData[i+4],FrameLen);
												break;
										}
										case CMD_SERVER_IP:
										{
												memset(deviceAttributeInfo.serverIP,0,sizeof(deviceAttributeInfo.serverIP));
												memcpy((char *)deviceAttributeInfo.serverIP, &RxFrameData[i+4],FrameLen);
												break;
										}
										case CMD_DEVICE_ID:
										{
												memset(deviceAttributeInfo.deviceID,0,sizeof(deviceAttributeInfo.deviceID));
												memcpy((char *)deviceAttributeInfo.deviceID, &RxFrameData[i+4],FrameLen);
												break;
										}
										case CMD_SERVER_PORT:
										{
												char temp[10];
												memcpy((char *)temp, &RxFrameData[i+4],FrameLen);
												deviceAttributeInfo.serverPort = RxFrameData[i+4] | RxFrameData[i+5] <<8;
												break;
										}
										case CMD_PICTURE_SIZE:
										{
												deviceAttributeInfo.picSize = RxFrameData[i+4] | RxFrameData[i+5] <<8;
												switch(deviceAttributeInfo.picSize)
												{
													case FRAMESIZE_QVGA:
													{
														deviceAttributeInfo.picWidth = 320;
														deviceAttributeInfo.picHeight = 240;
														break;
													}
													case FRAMESIZE_VGA:
													{
														deviceAttributeInfo.picWidth = 680;
														deviceAttributeInfo.picHeight = 480;
														break;
													}
													case FRAMESIZE_UXGA:
													{
														deviceAttributeInfo.picWidth = 1600;
														deviceAttributeInfo.picHeight = 1200;
														break;
													}
													case FRAMESIZE_QSXGA:
													{
														deviceAttributeInfo.picWidth = 2592;
														deviceAttributeInfo.picHeight = 1940;
														break;
													}
													default:
														break;
												}
												break;
										}
										case CMD_PICTURE_QUALITY:
										{
												deviceAttributeInfo.jpegQuality = RxFrameData[i+4] | RxFrameData[i+5] <<8;
												break;
										}
										case CMD_SET_LIED_BRIGHTNESS:
										{
												deviceAttributeInfo.ledFlashBrightness = RxFrameData[i+4] | RxFrameData[i+5] <<8;
												break;
										}
										case CMD_SET_TAKE_PICTURE_DELAY_TIME:
										{
												deviceAttributeInfo.takePictureDelayTime = RxFrameData[i+4] | RxFrameData[i+5] <<8;
												break;
										}
										case CMD_SET_PARA_END:			/* 设置参数接收完成 */
										{
												bsp_EraseCpuFlash((uint32_t)ADDR_FLASH_SECTOR_7_BANK2);
												bsp_WriteCpuFlash(ADDR_FLASH_SECTOR_7_BANK2,(uint8_t *)deviceAttributeInfo.wifiName,sizeof(deviceAttributeInfo));
												deviceAttributeInfo.recordTimeIndex = 0;
												deviceAttributeInfo.isSetRecordTime = 1;

												sprintf(logBuffer,"\xE5\x8F\x82\xE6\x95\xB0\xE8\xAE\xBE\xE7\xBD\xAE\xE6\x88\x90\xE5\x8A\x9F\xEF\xBC\x81");/* 参数设置成功！ */
												sendLogMessage(0xAA,MCU,CMD_LOG_MESSAGE,logBuffer);

												break;
										}
										case CMD_SHOW_DEVICE_INFO:
										{
												showDeviceInfo();
												break;
										}
										case CMD_RESET_DEVICE:
										{
												sendLogMessage(0xAA,MCU,CMD_LOG_MESSAGE,"\xe8\xae\xbe\xe5\xa4\x87\xe9\x87\x8d\xe5\x90\xaf");
												HAL_Delay(100);
												/* 系统复位 */
												NVIC_SystemReset();
												break;
										}
										case CMD_SET_RECORD_TIME:
										{
												if(deviceAttributeInfo.recordTimeIndex > 50)
												{
														break;
												}
												if(deviceAttributeInfo.isSetRecordTime == 1)
												{
													for(int i=0;i<50;i++)/* 间隔定时时清除固定定时设置的时间 */
													{
															memset(deviceAttributeInfo.recordTime[i],0,6);
													}
													deviceAttributeInfo.isSetRecordTime = 0;
												}
												memset((char *)deviceAttributeInfo.recordTime[deviceAttributeInfo.recordTimeIndex],0,6);
												memcpy((char *)deviceAttributeInfo.recordTime[deviceAttributeInfo.recordTimeIndex], &RxFrameData[i+4],FrameLen);
												deviceAttributeInfo.recordTime[deviceAttributeInfo.recordTimeIndex][5] = '\0';
												deviceAttributeInfo.recordTimeIndex++;
												deviceAttributeInfo.scheduledDeletion = 0;
												break;
										}
										case CMD_SET_DELAY_TIME:
										{
												deviceAttributeInfo.scheduledDeletion = RxFrameData[i+4] | RxFrameData[i+5] <<8;
												for(int i=0;i<50;i++)/* 间隔定时时清除固定定时设置的时间 */
												{
														memset(deviceAttributeInfo.recordTime[i],0,6);
												}
												break;
										}
									  case CMD_SET_TEST_MODE:				/* 设备工作在测试模式 */
										{
												deviceAttributeInfo.sysState = SYS_TEST_MODE_SATE;
												sprintf(logBuffer,"\xE5\xB7\xB2\xE8\xAE\xBE\xE7\xBD\xAE\xE5\xB7\xA5\xE4\xBD\x9C\xE5\x9C\xA8\xE6\xB5\x8B\xE8\xAF\x95\xE6\xA8\xA1\xE5\xBC\x8F");/* 已设置工作在测试模式 */
												sendLogMessage(0xAA,MCU,CMD_LOG_MESSAGE,logBuffer);
												break;
										}
										case CMD_SET_WORK_MODE:				/* 设备工作在工作模式 */
										{
												deviceAttributeInfo.sysState = SYS_OK_STATE;
												sprintf(logBuffer,"\xE5\xB7\xB2\xE8\xAE\xBE\xE7\xBD\xAE\xE5\xB7\xA5\xE4\xBD\x9C\xE5\x9C\xA8\xE5\xB7\xA5\xE4\xBD\x9C\xE6\xA8\xA1\xE5\xBC\x8F");/* 已设置工作在工作模式 */
												sendLogMessage(0xAA,MCU,CMD_LOG_MESSAGE,logBuffer);
												break;
										}
										case CMD_TAKE_PICTURE_TEST_MODE: /* 设备拍照 */
										{
												takePictureTestModeFlag = 1;
												sprintf(logBuffer,"\xE6\x94\xB6\xE5\x88\xB0\xE6\x8B\x8D\xE7\x85\xA7\xE6\x8C\x87\xE4\xBB\xA4");/* 收到拍照指令 */
												sendLogMessage(0xAA,MCU,CMD_LOG_MESSAGE,logBuffer);
												break;
										}
										case CMD_OPEN_MOTO_TEST_MODE: /* 设备打开电机 */
										{
												sprintf(logBuffer,"\xE6\x94\xB6\xE5\x88\xB0\xE6\x89\x93\xE5\xBC\x80\xE7\x94\xB5\xE6\x9C\xBA\xE5\x91\xBD\xE4\xBB\xA4");/* 收到打开电机命令 */
												sendLogMessage(0xAA,MCU,CMD_LOG_MESSAGE,logBuffer);
												break;
										}
										case CMD_RUN_IAP:               /* 运行IAP程序 */
										{
											sendLogMessage(0xAA,MCU,CMD_LOG_MESSAGE,"\xe8\xae\xbe\xe5\xa4\x87\xe9\x87\x8d\xe5\x90\xaf");

											bsp_EraseCpuFlash((uint32_t)ADDR_FLASH_SECTOR_7_BANK2);

											deviceAttributeInfo.iapState = IAP_RUN_STATE;

											bsp_WriteCpuFlash(ADDR_FLASH_SECTOR_7_BANK2,(uint8_t *)deviceAttributeInfo.wifiName,sizeof(deviceAttributeInfo));

											/* 系统复位 */
											 NVIC_SystemReset(); //复位
											break;
										}
										case CMD_SET_AUTO_FOCUS:
										{
												deviceAttributeInfo.automaticFocus =  RxFrameData[i+4] | RxFrameData[i+5] <<8;
												if(1 == deviceAttributeInfo.automaticFocus)
												{
													OV5640_Focus_Constant();
													OV5640_Focus_Init();
												}
												break;
										}
										case CMD_SET_CAMERA_PICTURE_DIRECTION:
										{
												deviceAttributeInfo.pictureDirection =  RxFrameData[i+4] | RxFrameData[i+5] <<8;
												switch(deviceAttributeInfo.pictureDirection)
												{
													case 0:
													{
														ov5640Normal();
														break;
													}
													case 1:
													{
														ov5640Mirror();
														break;
													}
													case 2:
													{
														ov5640Flip();
														break;
													}
													case 3:
													{
														ov5640MirrorAndFlip();
														break;
													}
													default:
														break;
												}
												break;
										}
										default:
												break;
								}
							}
							i += OneFrameDataLen-1;										/*偏移*/
						}
					}
					else
					{
						WriteBytes(ringbuffer,&RxFrameData[i],FrameDataLen - i);/*未处理的数据写回缓冲区*/
						vPortFree(RxFrameData);  //释放内存
						return ;
					}
				}
			}
		}
		vPortFree(RxFrameData);  //释放内存
	}
}
/* 显示设备设置的属性 */
static void showDeviceInfo(void)
{
	char logBuffer[100];
	sprintf(logBuffer,"\xE5\xBD\x93\xE5\x89\x8D\xE8\xAE\xBE\xE5\xA4\x87\xE4\xBF\xA1\xE6\x81\xAF\xE5\xA6\x82\xE4\xB8\x8B\xEF\xBC\x9A");/* 当前设备信息如下： */
	sendLogMessage(0xAA,MCU,CMD_LOG_MESSAGE,logBuffer);

	memset(logBuffer,0,sizeof(logBuffer));
	sprintf(logBuffer,"\x57\x49\x46\x49\xE5\x90\x8D\xE7\xA7\xB0\xE4\xB8\xBA\x3A%s",deviceAttributeInfo.wifiName);
	sendLogMessage(0xAA,MCU,CMD_LOG_MESSAGE,logBuffer);

	memset(logBuffer,0,sizeof(logBuffer));
	sprintf(logBuffer,"\x57\x49\x46\x49\xE5\xAF\x86\xE7\xA0\x81\xE4\xB8\xBA\x3A%s",deviceAttributeInfo.wifiPssword);
	sendLogMessage(0xAA,MCU,CMD_LOG_MESSAGE,logBuffer);

	memset(logBuffer,0,sizeof(logBuffer));
	sprintf(logBuffer,"\xE6\x9C\x8D\xE5\x8A\xA1\xE5\x99\xA8\xE5\x9C\xB0\xE5\x9D\x80\xE4\xB8\xBA\x3A%s",deviceAttributeInfo.serverIP);
	sendLogMessage(0xAA,MCU,CMD_LOG_MESSAGE,logBuffer);

	memset(logBuffer,0,sizeof(logBuffer));
	sprintf(logBuffer,"\xE6\x9C\x8D\xE5\x8A\xA1\xE5\x99\xA8\xE7\xAB\xAF\xE5\x8F\xA3\xE4\xB8\xBA\x3A%04d",deviceAttributeInfo.serverPort);
	sendLogMessage(0xAA,MCU,CMD_LOG_MESSAGE,logBuffer);

	memset(logBuffer,0,sizeof(logBuffer));
	sprintf(logBuffer,"\xE8\xAE\xBE\xE5\xA4\x87\x49\x44\xE4\xB8\xBA\x3A%s",deviceAttributeInfo.deviceID);
	sendLogMessage(0xAA,MCU,CMD_LOG_MESSAGE,logBuffer);

	memset(logBuffer,0,sizeof(logBuffer));
	sprintf(logBuffer,"\xE9\x97\xAA\xE5\x85\x89\xE7\x81\xAF\xE4\xBA\xAE\xE5\xBA\xa6\xE4\xB8\xBA\x3A%04d",deviceAttributeInfo.ledFlashBrightness);
	sendLogMessage(0xAA,MCU,CMD_LOG_MESSAGE,logBuffer);

	memset(logBuffer,0,sizeof(logBuffer));
	sprintf(logBuffer,"\xE6\x8B\x8D\xE7\x85\xA7\xE7\x9A\x84\xE5\xBB\xB6\xE6\x97\xB6\xE6\x97\xB6\xE9\x97\xB4\xE4\xB8\xBA\x3A%04d",deviceAttributeInfo.takePictureDelayTime);
	sendLogMessage(0xAA,MCU,CMD_LOG_MESSAGE,logBuffer);

	/* 发送图片压缩质量 */
	memset(logBuffer,0,sizeof(logBuffer));
	sprintf(logBuffer,"\xe5\x9b\xbe\xe5\x83\x8f\xe5\x8e\x8b\xe7\xbc\xa9\xe8\xb4\xa8\xe9\x87\x8f\x3A%04d",deviceAttributeInfo.jpegQuality);
	sendLogMessage(0xAA,MCU,CMD_LOG_MESSAGE,logBuffer);
	/* 发送图片尺寸 */
	memset(logBuffer,0,sizeof(logBuffer));
	sprintf(logBuffer,"\xe5\x9b\xbe\xe5\x83\x8f\xe5\xb0\xba\xe5\xaf\xb8\x3A%04d\x2a%04d",deviceAttributeInfo.picWidth,deviceAttributeInfo.picHeight);
	sendLogMessage(0xAA,MCU,CMD_LOG_MESSAGE,logBuffer);
	/* JPEG压缩质量 */
	memset(logBuffer,0,sizeof(logBuffer));
	sprintf(logBuffer,"\xe5\x9b\xbe\xe5\x83\x8f\xe5\x8e\x8b\xe7\xbc\xa9\xe8\xb4\xa8\xe9\x87\x8f\x3A%04d",deviceAttributeInfo.jpegQuality);
	sendLogMessage(0xAA,MCU,CMD_LOG_MESSAGE,logBuffer);
	/* 读取系统时间 */
	memset(logBuffer,0,sizeof(logBuffer));
	sprintf(logBuffer,"\xe7\xb3\xbb\xe7\xbb\x9f\xe6\x97\xb6\xe9\x97\xb4\xe4\xb8\xba\x3a %02d\x3a%02d\x3a%02d",time.hour,time.minute,time.second);
	sendLogMessage(0xAA,MCU,CMD_LOG_MESSAGE,logBuffer);
	switch(deviceAttributeInfo.pictureDirection)
	{
		case 0:
		{
			sendLogMessage(0xAA,MCU,CMD_LOG_MESSAGE,"\xe5\x9b\xbe\xe7\x89\x87\xe6\x96\xb9\xe5\x90\x91\xe6\xad\xa3\xe5\xb8\xb8");	/* 图片方向正常 */
			break;
		}
		case 1:
		{
			sendLogMessage(0xAA,MCU,CMD_LOG_MESSAGE,"\xe5\x9b\xbe\xe7\x89\x87\xe6\x96\xb9\xe5\x90\x91\xe9\x95\x9c\xe5\x83\x8f");/* 图片方向镜像 */
			break;
		}
		case 2:
		{
			sendLogMessage(0xAA,MCU,CMD_LOG_MESSAGE,"\xe5\x9b\xbe\xe7\x89\x87\xe6\x96\xb9\xe5\x90\x91\xe7\xbf\xbb\xe8\xbd\xac");/* 图片方向翻转 */
			break;
		}
		case 3:
		{
			sendLogMessage(0xAA,MCU,CMD_LOG_MESSAGE,"\xe5\x9b\xbe\xe7\x89\x87\xe6\x96\xb9\xe5\x90\x91\xe9\x95\x9c\xe5\x83\x8f\xe7\xbf\xbb\xe8\xbd\xac");/* 图片方向镜像翻转 */
			break;
		}
		default:
			break;
	}
	/* 固定定时组 */
	memset(logBuffer,0,sizeof(logBuffer));
	sprintf(logBuffer,"\xE5\x9B\xBA\xE5\xAE\x9A\xE5\xAE\x9A\xE6\x97\xB6\xE7\xBB\x84\xE4\xB8\xBA\x3A");
	sendLogMessage(0xAA,MCU,CMD_LOG_MESSAGE,logBuffer);

	for(uint32_t i=0;i<50;i++)
	{
		if(deviceAttributeInfo.recordTime[i][0] != 0)
		{
			memset(logBuffer,0,sizeof(logBuffer));
			sprintf(logBuffer,"%s",&deviceAttributeInfo.recordTime[i][0]);
			sendLogMessage(0xAA,MCU,CMD_LOG_MESSAGE,logBuffer);
		}
	}
	memset(logBuffer,0,sizeof(logBuffer));
	sprintf(logBuffer,"\xE9\x97\xB4\xE9\x9A\x94\xE5\xAE\x9A\xE6\x97\xB6\xE4\xB8\xBA\x3A%04d",deviceAttributeInfo.scheduledDeletion);
	sendLogMessage(0xAA,MCU,CMD_LOG_MESSAGE,logBuffer);

	/* 发送当前运行在APP程序的状态 */
	vcpSendData(0xAA,MCU,CMD_NOW_APP_STATE,0,0);
}
static uint8_t sendLogMessage(unsigned char frameHead, unsigned char frameAddress, unsigned char frameID, char* data)
{
    unsigned char frameDataLen = 0;
		uint32_t cnt = 0;
    char frameData[260];
    frameDataLen = strlen(data);
    frameData[cnt++] = frameHead;                               /* 帧头 */
    frameData[cnt++] = frameAddress;                            /* 帧地址 */
    frameData[cnt++] = frameID;                                 /* 帧ID */
    frameData[cnt++] = frameDataLen;                            /* 帧数据长度 */

		memcpy(&frameData[4],data,frameDataLen);

    unsigned char sumcheck = 0;
    unsigned char addcheck = 0;
    for(unsigned char i=0; i < frameData[3] + 4 ; i++)
    {
        sumcheck += frameData[i]; //从帧头开始，对每一字节进行求和，直到DATA区结束
        addcheck += sumcheck; //每一字节的求和操作，进行一次sumcheck的累加
    }
    frameData[frameDataLen + 4] = sumcheck;
    frameData[frameDataLen + 5] = addcheck;

		while(USBD_OK != CDC_Transmit_HS((uint8_t *)frameData,frameDataLen + 4 + 2)){};
    return frameDataLen + 4 + 2;
}
/* 虚拟串口发送数据 */
static uint8_t vcpSendData(uint8_t frameHead, uint8_t frameAddress, uint8_t frameID, uint8_t* data,uint8_t dataLen)
{
		uint32_t cnt = 0;
    uint8_t frameData[260];

    frameData[cnt++] = frameHead;                               /* 帧头 */
    frameData[cnt++] = frameAddress;                            /* 帧地址 */
    frameData[cnt++] = frameID;                                 /* 帧ID */
    frameData[cnt++] = dataLen;                            /* 帧数据长度 */

		memcpy(&frameData[4],data,dataLen);

    unsigned char sumcheck = 0;
    unsigned char addcheck = 0;
    for(unsigned char i=0; i < frameData[3] + 4 ; i++)
    {
        sumcheck += frameData[i]; //从帧头开始，对每一字节进行求和，直到DATA区结束
        addcheck += sumcheck; //每一字节的求和操作，进行一次sumcheck的累加
    }
    frameData[dataLen + 4] = sumcheck;
    frameData[dataLen + 5] = addcheck;

		while(USBD_OK != CDC_Transmit_HS((uint8_t *)frameData,dataLen + 4 + 2)){};
    return dataLen + 4 + 2;
}

/*
	usart1DataAnalysis(_RingBuffer *ringbuffer)
	功能:解析USART1串口接收的数据
*/
static void usart1DataAnalysis(_RingBuffer *ringbuffer)
{
	unsigned char *FrameData;                                               /* 存储解析帧的空间 */
	unsigned short allFrameDataLen = ringbuffer->Lenght;               			/* 获取缓冲区中的存储的数据长度 */
	uint32_t index = 0;																											/* 数组中的偏移位置 */

	if(xPortGetFreeHeapSize() >= allFrameDataLen)                           /* 判断剩余内存是否大于申请内存 */
	{
			FrameData = (unsigned char *)pvPortMalloc(allFrameDataLen);	        /* 为读取缓冲区中的所有数据申请内存 */
			if(ReadBytes(ringbuffer,FrameData,allFrameDataLen) == 1)						/* 读取缓冲区中的所有数据 */
			{
				for(uint32_t i=0;i<allFrameDataLen;i++)														/*  */
				{
					if((0xAA == FrameData[i]) && (allFrameDataLen - i >= 8))				/* 确认数据帧头同时能得到数据长度 */
					{
						uint32_t dataLen = FrameData[i+4] | FrameData[i+5]<<8 | FrameData[i+6]<<16 | FrameData[i+7]<<24;
						if(allFrameDataLen - i >= 8+dataLen+1)                        /* 能都得到整个帧的数据长度 */
            {
                if(0xBB == FrameData[i+8+dataLen])                				/* 确认数据帧尾 */
                {
                    frameDataAnalysis(&FrameData[i],9+dataLen);      			/* 分析帧的数据 */
                }
                i = i + dataLen + 8;                                      /* 偏移 */
								index = i;
								break;
            }
					}
				}
				WriteBytes(ringbuffer,&FrameData[index],allFrameDataLen - index);
			}
			vPortFree(FrameData);  //释放内存
	}
}
static void frameDataAnalysis(uint8_t *data,uint32_t dataLen)
{
	switch(data[2])
	{
			case SERVER_TO_CLIENT:                      /* 服务器到摄像头 */
			{
				serverToClient(data);
				break;
			}
			case PC_TO_CAMER:                           /* pc到camera */
			{
				pcToCameraDeal(data);
				break;
			}
			default:
				break;
	}
}
static void serverToClient(uint8_t *data)
{
	switch(data[3])
	{
		case SERVER_CHECK_BACK:                           /* server到client */
		{
			serverIsOk = 0;
			break;
		}
		default:
				break;
	}
}
static void pcToCameraDeal(uint8_t *data)
{
	switch(data[3])
	{
		case TAKE_PICTURE:                           /* pc到camera */
		{
			getTackPictureFlag = 1;
			break;
		}
		case SET_RECORD_TIME:                           /* pc到camera */
		{
			uint32_t dataLen = data[4] | data[5]<<8 | data[6]<<16 | data[7]<<24;
			if(deviceAttributeInfo.recordTimeIndex > 50)
			{
					break;
			}
			if(deviceAttributeInfo.isSetRecordTime == 1)
			{
				for(int i=0;i<50;i++)/* 间隔定时时清除固定定时设置的时间 */
				{
						memset(deviceAttributeInfo.recordTime[i],0,6);
				}
				deviceAttributeInfo.isSetRecordTime = 0;
			}
			memset((char *)deviceAttributeInfo.recordTime[deviceAttributeInfo.recordTimeIndex],0,6);
			memcpy((char *)deviceAttributeInfo.recordTime[deviceAttributeInfo.recordTimeIndex], &data[8],dataLen);
			deviceAttributeInfo.recordTime[deviceAttributeInfo.recordTimeIndex][5] = '\0';
			deviceAttributeInfo.recordTimeIndex++;
			deviceAttributeInfo.scheduledDeletion = 0;
			break;
		}
		case SET_RECORD_TIME_END:                           /* pc到camera */
		{
			deviceAttributeInfo.recordTimeIndex = 0;
			deviceAttributeInfo.isSetRecordTime = 1;
			packTcpDataFrameAndSend(DEVICE_LABEL_CAMERA,CAMER_TO_PC,SET_RECORD_TIME_SUCCESS,0,0);
			bsp_EraseCpuFlash((uint32_t)ADDR_FLASH_SECTOR_7_BANK2);
			bsp_WriteCpuFlash(ADDR_FLASH_SECTOR_7_BANK2,(unsigned char *)deviceAttributeInfo.wifiName,sizeof(_deviceInfo));
			break;
		}
		case SET_SCHEDULED_TIME:                           /* pc到camera */
		{
			deviceAttributeInfo.scheduledDeletion = data[8] | data[9] <<8;
			for(int i=0;i<50;i++)/* 间隔定时时清除固定定时设置的时间 */
			{
					memset(deviceAttributeInfo.recordTime[i],0,6);
			}
			packTcpDataFrameAndSend(DEVICE_LABEL_CAMERA,CAMER_TO_PC,SET_SCHEDULED_TIME_CMD_SUCCESS,0,0);
			bsp_EraseCpuFlash((uint32_t)ADDR_FLASH_SECTOR_7_BANK2);
			bsp_WriteCpuFlash(ADDR_FLASH_SECTOR_7_BANK2,(unsigned char *)deviceAttributeInfo.wifiName,sizeof(_deviceInfo));
			break;
		}
		case OPEN_MOTO_CMD:
		{
			openMotoFlag = 1;
			packTcpDataFrameAndSend(DEVICE_LABEL_CAMERA,CAMER_TO_PC,OPEN_MOTO_SUCCESS_CMD,0,0);
			break;
		}
		default:
			break;
	}
}
/* 给发送的TCP数据封帧，同时将数据推送出去 */
static void packTcpDataFrameAndSend(uint8_t charactar,uint8_t target, uint8_t cmd, uint32_t dataLen, uint8_t *data)
{
	/* 因为TCP数据包的数据量大，同时又因为单片机的内存岌岌可危，采用使用不同内存段来实现发送 */
	/* 0xAA byte1 byte2 byte3  byte4 byte5 byte6 byte7   byteN   0xBB */
	/* 帧头  角色   目标   作用       长度（四字节）          数据载荷   帧尾 */
	uint8_t tempData[20];
	uint32_t cnt = 0;
	tempData[cnt++] = 0xAA;                 /* 帧头 */
	tempData[cnt++] = charactar;      			/* 角色 */
	tempData[cnt++] = target;               /* 目标 */
	tempData[cnt++] = cmd;                  /* 作用 */
	tempData[cnt++] = dataLen;              /* 长度 */
	tempData[cnt++] = dataLen>>8;
	tempData[cnt++] = dataLen>>16;
	tempData[cnt++] = dataLen>>24;
	uint8_t reTryCnt = 0;
	while(HAL_OK != HAL_UART_Transmit(&huart1,(const uint8_t *)tempData,8,0xFFFFFFFF) && reTryCnt <5)
	{
		reTryCnt++;
	}
	if(0 != dataLen)
	{
		reTryCnt = 0;
		while(HAL_OK != HAL_UART_Transmit(&huart1,(const uint8_t *)data,dataLen,0xFFFFFFFF) && reTryCnt <5)
		{
			reTryCnt++;
		}
	}
	reTryCnt = 0;
	tempData[0] = 0xBB;
	while(HAL_OK != HAL_UART_Transmit(&huart1,(const uint8_t *)tempData,1,0xFFFFFFFF) && reTryCnt <5)
	{
		reTryCnt++;
	}
}

static void takePictureOnTestMode(void)
{
	__HAL_TIM_SetCompare(&htim2, TIM_CHANNEL_4, deviceAttributeInfo.ledFlashBrightness);
	__HAL_TIM_SetCompare(&htim4, TIM_CHANNEL_1, deviceAttributeInfo.ledFlashBrightness);

	JPEG_ConfTypeDef    jpeg_info;
	JPEG_RGBToYCbCr_Convert_Function pRGBToYCbCr_Convert_Function;
	uint32_t MCU_TotalNb=0;
	uint32_t ConvertedDataCount=0;

	uint8_t *tempP = NULL;
	uint8_t *jpegStart = NULL;
	uint8_t *jpegEnd = NULL;
	uint32_t jpegLen = 0;

	/* 设置裁剪的感兴趣区域 */
	if(0 == deviceAttributeInfo.picWidth || 0 == deviceAttributeInfo.picHeight)
	{
		deviceAttributeInfo.picWidth = 2592;
		deviceAttributeInfo.picHeight = 1940;
	}

	uint32_t picStartX = 0;
	uint32_t picStartY = 0;

	picStartX = (2592 - deviceAttributeInfo.picWidth)/2;
	picStartY = (1940 - deviceAttributeInfo.picHeight)/2;

	for(uint8_t i=0;i<5;i++)
	{
		if(1 == deviceAttributeInfo.automaticFocus)	/* 自动对焦有效 */
		{
			OV5640_Focus_Single();
		}

		HAL_DCMI_DisableCrop(&hdcmi);
		HAL_Delay(1);
		HAL_DCMI_ConfigCrop (&hdcmi,picStartX,picStartY,deviceAttributeInfo.picWidth*2-1,deviceAttributeInfo.picHeight-1);
		HAL_Delay(1);
		HAL_DCMI_EnableCrop (&hdcmi);
		HAL_Delay(1);

		HAL_DCMI_Start_DMA(&hdcmi,DCMI_MODE_SNAPSHOT,(uint32_t)&dcmi_data_buff,deviceAttributeInfo.picWidth * deviceAttributeInfo.picHeight / 2);
		while ((DCMI->CR & DCMI_CR_CAPTURE) != 0) {};
		HAL_DCMI_Stop(&hdcmi);
	}

	__HAL_TIM_SetCompare(&htim2, TIM_CHANNEL_4, 0);
	__HAL_TIM_SetCompare(&htim4, TIM_CHANNEL_1, 0);

	jpeg_info.ImageWidth = deviceAttributeInfo.picWidth;
	jpeg_info.ImageHeight = deviceAttributeInfo.picHeight;
	jpeg_info.ChromaSubsampling = JPEG_420_SUBSAMPLING;
	jpeg_info.ColorSpace = JPEG_YCBCR_COLORSPACE;
	jpeg_info.ImageQuality = deviceAttributeInfo.jpegQuality;
	HAL_JPEG_ConfigEncoding(&hjpeg, &jpeg_info);

	//根据编码信息，获取编码函数和数量
	JPEG_GetEncodeColorConvertFunc(&jpeg_info, &pRGBToYCbCr_Convert_Function, &MCU_TotalNb);

	//预处理，将RGB转换为指定的YUV格式
	pRGBToYCbCr_Convert_Function((uint8_t *)dcmi_data_buff, (uint8_t *)jpgDataBuffer, 0, deviceAttributeInfo.picWidth * deviceAttributeInfo.picHeight * 2,&ConvertedDataCount);

	HAL_JPEG_Encode(&hjpeg,(uint8_t *)jpgDataBuffer,ConvertedDataCount,(uint8_t *)dcmi_data_buff,JPG_DATA_BUFFER_SIZE,HAL_MAX_DELAY);

	tempP = (unsigned char *)dcmi_data_buff;
	jpegLen = 0;
	jpegStart = NULL;
	jpegEnd = NULL;
	for(int i=0;i<JPG_DATA_BUFFER_SIZE;)
	{
		if(0xFF == tempP[i] && 0xD8 == tempP[i+1])
		{
			jpegStart = &tempP[i];
		}
		if(0xFF == tempP[i] && 0xD9 == tempP[i+1])
		{
			jpegEnd = &tempP[i+1];
			break;
		}
		i++;
	}
	if(NULL != jpegStart && NULL != jpegEnd)								/* 判断数据检测是否有效 */
	{
		jpegLen = jpegEnd - jpegStart + 1;
	}

	if(jpegLen)																							/* 数据有效 */
	{
		uint8_t tempVcpSendDataBuffer[260];
		tempVcpSendDataBuffer[0] = jpegLen;
		tempVcpSendDataBuffer[1] = jpegLen >> 8;
		tempVcpSendDataBuffer[2] = jpegLen >> 16;
		tempVcpSendDataBuffer[3] = jpegLen >> 24;
		vcpSendData(0xAA,MCU,CMD_JPEG_DATA_PACK_SIZE,tempVcpSendDataBuffer,4);			/* 发送图片大小 */

		uint32_t clcTimes = 0;
		clcTimes = jpegLen / 240;
		for(int i=0;i<clcTimes;i++)
		{
			vcpSendData(0xAA,MCU,CMD_JPEG_DATA_PACK,jpegStart,240);
			jpegStart += 240;
		}
		jpegLen = jpegLen % 240;

		vcpSendData(0xAA,MCU,CMD_JPEG_DATA_PACK,jpegStart,jpegLen);
		vcpSendData(0xAA,MCU,CMD_JPEG_DATA_SEND_END,0,0);														/* 告知发送结束 */
	}
}
static void takePictureCameraToPc(void)
{
	__HAL_TIM_SetCompare(&htim2, TIM_CHANNEL_4, deviceAttributeInfo.ledFlashBrightness);
	__HAL_TIM_SetCompare(&htim4, TIM_CHANNEL_1, deviceAttributeInfo.ledFlashBrightness);

	JPEG_ConfTypeDef    jpeg_info;
	JPEG_RGBToYCbCr_Convert_Function pRGBToYCbCr_Convert_Function;
	uint32_t MCU_TotalNb=0;
	uint32_t ConvertedDataCount=0;

	uint8_t *tempP = NULL;
	uint8_t *jpegStart = NULL;
	uint8_t *jpegEnd = NULL;
	uint32_t jpegLen = 0;

	/* 设置裁剪的感兴趣区域 */
	if(0 == deviceAttributeInfo.picWidth || 0 == deviceAttributeInfo.picHeight)
	{
		deviceAttributeInfo.picWidth = 2592;
		deviceAttributeInfo.picHeight = 1940;
	}

	uint32_t picStartX = 0;
	uint32_t picStartY = 0;

	picStartX = (2592 - deviceAttributeInfo.picWidth)/2;
	picStartY = (1940 - deviceAttributeInfo.picHeight)/2;

	for(uint8_t i=0;i<5;i++)
	{
		if(1 == deviceAttributeInfo.automaticFocus)	/* 自动对焦有效 */
		{
			OV5640_Focus_Single();
		}

		HAL_DCMI_DisableCrop(&hdcmi);
		HAL_Delay(1);
		HAL_DCMI_ConfigCrop (&hdcmi,picStartX,picStartY,deviceAttributeInfo.picWidth*2-1,deviceAttributeInfo.picHeight-1);
		HAL_Delay(1);
		HAL_DCMI_EnableCrop (&hdcmi);
		HAL_Delay(1);

		HAL_DCMI_Start_DMA(&hdcmi,DCMI_MODE_SNAPSHOT,(uint32_t)&dcmi_data_buff,deviceAttributeInfo.picWidth * deviceAttributeInfo.picHeight / 2);
		while ((DCMI->CR & DCMI_CR_CAPTURE) != 0) {};
		HAL_DCMI_Stop(&hdcmi);
	}

	__HAL_TIM_SetCompare(&htim2, TIM_CHANNEL_4, 0);
	__HAL_TIM_SetCompare(&htim4, TIM_CHANNEL_1, 0);

	jpeg_info.ImageWidth = deviceAttributeInfo.picWidth;
	jpeg_info.ImageHeight = deviceAttributeInfo.picHeight;
	jpeg_info.ChromaSubsampling = JPEG_420_SUBSAMPLING;
	jpeg_info.ColorSpace = JPEG_YCBCR_COLORSPACE;
	jpeg_info.ImageQuality = deviceAttributeInfo.jpegQuality;
	HAL_JPEG_ConfigEncoding(&hjpeg, &jpeg_info);

	//根据编码信息，获取编码函数和数量
	JPEG_GetEncodeColorConvertFunc(&jpeg_info, &pRGBToYCbCr_Convert_Function, &MCU_TotalNb);

	//预处理，将RGB转换为指定的YUV格式
	pRGBToYCbCr_Convert_Function((uint8_t *)dcmi_data_buff, (uint8_t *)jpgDataBuffer, 0, deviceAttributeInfo.picWidth * deviceAttributeInfo.picHeight * 2,&ConvertedDataCount);

	HAL_JPEG_Encode(&hjpeg,(uint8_t *)jpgDataBuffer,ConvertedDataCount,(uint8_t *)dcmi_data_buff,JPG_DATA_BUFFER_SIZE,HAL_MAX_DELAY);

	tempP = (unsigned char *)dcmi_data_buff;
	jpegLen = 0;
	jpegStart = NULL;
	jpegEnd = NULL;
	for(int i=0;i<JPG_DATA_BUFFER_SIZE;)
	{
		if(0xFF == tempP[i] && 0xD8 == tempP[i+1])
		{
			jpegStart = &tempP[i];
		}
		if(0xFF == tempP[i] && 0xD9 == tempP[i+1])
		{
			jpegEnd = &tempP[i+1];
			break;
		}
		i++;
	}
	if(NULL != jpegStart && NULL != jpegEnd)								/* 判断数据检测是否有效 */
	{
		jpegLen = jpegEnd - jpegStart + 1;
	}

	if(jpegLen)																							/* 数据有效 */
	{
		uint8_t jpegDataLen[4];
		jpegDataLen[0] = jpegLen;
		jpegDataLen[1] = jpegLen >> 8;
		jpegDataLen[2] = jpegLen >> 16;
		jpegDataLen[3] = jpegLen >> 24;

		packTcpDataFrameAndSend(DEVICE_LABEL_CAMERA,CAMER_TO_PC,JPEG_DATA_PACK_SIZE,4,jpegDataLen);/* 发送图片大小 */

		uint32_t clcTimes = 0;
		clcTimes = jpegLen / 64000;
		for(int i=0;i<clcTimes;i++)
		{
			packTcpDataFrameAndSend(DEVICE_LABEL_CAMERA,CAMER_TO_PC,PICTURE_DATA_PACK,64000,jpegStart);
			jpegStart += 64000;
		}
		jpegLen = jpegLen % 64000;

		packTcpDataFrameAndSend(DEVICE_LABEL_CAMERA,CAMER_TO_PC,PICTURE_DATA_PACK,jpegLen,jpegStart);

		packTcpDataFrameAndSend(DEVICE_LABEL_CAMERA,CAMER_TO_PC,TAKE_PICTURE_END,0,0);/* 告知发送结束 */
	}
}

static void takePictureCameraToServer(void)
{
	__HAL_TIM_SetCompare(&htim2, TIM_CHANNEL_4, deviceAttributeInfo.ledFlashBrightness);
	__HAL_TIM_SetCompare(&htim4, TIM_CHANNEL_1, deviceAttributeInfo.ledFlashBrightness);

	JPEG_ConfTypeDef    jpeg_info;
	JPEG_RGBToYCbCr_Convert_Function pRGBToYCbCr_Convert_Function;
	uint32_t MCU_TotalNb=0;
	uint32_t ConvertedDataCount=0;

	uint8_t *tempP = NULL;
	uint8_t *jpegStart = NULL;
	uint8_t *jpegEnd = NULL;
	uint32_t jpegLen = 0;

	/* 设置裁剪的感兴趣区域 */
	if(0 == deviceAttributeInfo.picWidth || 0 == deviceAttributeInfo.picHeight)
	{
		deviceAttributeInfo.picWidth = 2592;
		deviceAttributeInfo.picHeight = 1940;
	}

	uint32_t picStartX = 0;
	uint32_t picStartY = 0;

	picStartX = (2592 - deviceAttributeInfo.picWidth)/2;
	picStartY = (1940 - deviceAttributeInfo.picHeight)/2;

	for(uint8_t i=0;i<5;i++)
	{
		if(1 == deviceAttributeInfo.automaticFocus)	/* 自动对焦有效 */
		{
			OV5640_Focus_Single();
		}

		HAL_DCMI_DisableCrop(&hdcmi);
		HAL_Delay(1);
		HAL_DCMI_ConfigCrop (&hdcmi,picStartX,picStartY,deviceAttributeInfo.picWidth*2-1,deviceAttributeInfo.picHeight-1);
		HAL_Delay(1);
		HAL_DCMI_EnableCrop (&hdcmi);
		HAL_Delay(1);

		HAL_DCMI_Start_DMA(&hdcmi,DCMI_MODE_SNAPSHOT,(uint32_t)&dcmi_data_buff,deviceAttributeInfo.picWidth * deviceAttributeInfo.picHeight / 2);
		while ((DCMI->CR & DCMI_CR_CAPTURE) != 0) {};
		HAL_DCMI_Stop(&hdcmi);
	}

	__HAL_TIM_SetCompare(&htim2, TIM_CHANNEL_4, 0);
	__HAL_TIM_SetCompare(&htim4, TIM_CHANNEL_1, 0);

	jpeg_info.ImageWidth = deviceAttributeInfo.picWidth;
	jpeg_info.ImageHeight = deviceAttributeInfo.picHeight;
	jpeg_info.ChromaSubsampling = JPEG_420_SUBSAMPLING;
	jpeg_info.ColorSpace = JPEG_YCBCR_COLORSPACE;
	jpeg_info.ImageQuality = deviceAttributeInfo.jpegQuality;
	HAL_JPEG_ConfigEncoding(&hjpeg, &jpeg_info);

	//根据编码信息，获取编码函数和数量
	JPEG_GetEncodeColorConvertFunc(&jpeg_info, &pRGBToYCbCr_Convert_Function, &MCU_TotalNb);

	//预处理，将RGB转换为指定的YUV格式
	pRGBToYCbCr_Convert_Function((uint8_t *)dcmi_data_buff, (uint8_t *)jpgDataBuffer, 0, deviceAttributeInfo.picWidth * deviceAttributeInfo.picHeight * 2,&ConvertedDataCount);

	HAL_JPEG_Encode(&hjpeg,(uint8_t *)jpgDataBuffer,ConvertedDataCount,(uint8_t *)dcmi_data_buff,JPG_DATA_BUFFER_SIZE,HAL_MAX_DELAY);

	tempP = (unsigned char *)dcmi_data_buff;
	jpegLen = 0;
	jpegStart = NULL;
	jpegEnd = NULL;
	for(int i=0;i<JPG_DATA_BUFFER_SIZE;)
	{
		if(0xFF == tempP[i] && 0xD8 == tempP[i+1])
		{
			jpegStart = &tempP[i];
		}
		if(0xFF == tempP[i] && 0xD9 == tempP[i+1])
		{
			jpegEnd = &tempP[i+1];
			break;
		}
		i++;
	}
	if(NULL != jpegStart && NULL != jpegEnd)								/* 判断数据检测是否有效 */
	{
		jpegLen = jpegEnd - jpegStart + 1;
	}

	if(jpegLen)																							/* 数据有效 */
	{
		uint8_t jpegDataLen[4];
		jpegDataLen[0] = jpegLen;
		jpegDataLen[1] = jpegLen >> 8;
		jpegDataLen[2] = jpegLen >> 16;
		jpegDataLen[3] = jpegLen >> 24;

		packTcpDataFrameAndSend(DEVICE_LABEL_CAMERA,CAMER_TO_SERVER,JPEG_DATA_PACK_SIZE,4,jpegDataLen);/* 发送图片大小 */

		uint32_t clcTimes = 0;
		clcTimes = jpegLen / 64000;
		for(int i=0;i<clcTimes;i++)
		{
			packTcpDataFrameAndSend(DEVICE_LABEL_CAMERA,CAMER_TO_SERVER,PICTURE_DATA_PACK,64000,jpegStart);
			jpegStart += 64000;
		}
		jpegLen = jpegLen % 64000;

		packTcpDataFrameAndSend(DEVICE_LABEL_CAMERA,CAMER_TO_SERVER,PICTURE_DATA_PACK,jpegLen,jpegStart);

		packTcpDataFrameAndSend(DEVICE_LABEL_CAMERA,CAMER_TO_SERVER,TAKE_PICTURE_END,0,0);/* 告知发送结束 */
	}
}
static void skipFrame(void)
{
	__HAL_TIM_SetCompare(&htim2, TIM_CHANNEL_4, deviceAttributeInfo.ledFlashBrightness);
	__HAL_TIM_SetCompare(&htim4, TIM_CHANNEL_1, deviceAttributeInfo.ledFlashBrightness);

	/* 设置裁剪的感兴趣区域 */
	if(0 == deviceAttributeInfo.picWidth || 0 == deviceAttributeInfo.picHeight)
	{
		deviceAttributeInfo.picWidth = 2592;
		deviceAttributeInfo.picHeight = 1940;
	}

	uint32_t picStartX = 0;
	uint32_t picStartY = 0;

	picStartX = (2592 - deviceAttributeInfo.picWidth)/2;
	picStartY = (1940 - deviceAttributeInfo.picHeight)/2;

	for(uint8_t i=0;i<5;i++)
	{
		if(1 == deviceAttributeInfo.automaticFocus)	/* 自动对焦有效 */
		{
			OV5640_Focus_Single();
		}

		HAL_DCMI_DisableCrop(&hdcmi);
		HAL_Delay(1);
		HAL_DCMI_ConfigCrop (&hdcmi,picStartX,picStartY,deviceAttributeInfo.picWidth*2-1,deviceAttributeInfo.picHeight-1);
		HAL_Delay(1);
		HAL_DCMI_EnableCrop (&hdcmi);
		HAL_Delay(1);

		HAL_DCMI_Start_DMA(&hdcmi,DCMI_MODE_SNAPSHOT,(uint32_t)&dcmi_data_buff,deviceAttributeInfo.picWidth * deviceAttributeInfo.picHeight / 2);
		while ((DCMI->CR & DCMI_CR_CAPTURE) != 0) {};
		HAL_DCMI_Stop(&hdcmi);
	}

	__HAL_TIM_SetCompare(&htim2, TIM_CHANNEL_4, 0);
	__HAL_TIM_SetCompare(&htim4, TIM_CHANNEL_1, 0);

}
/* USER CODE END Application */
